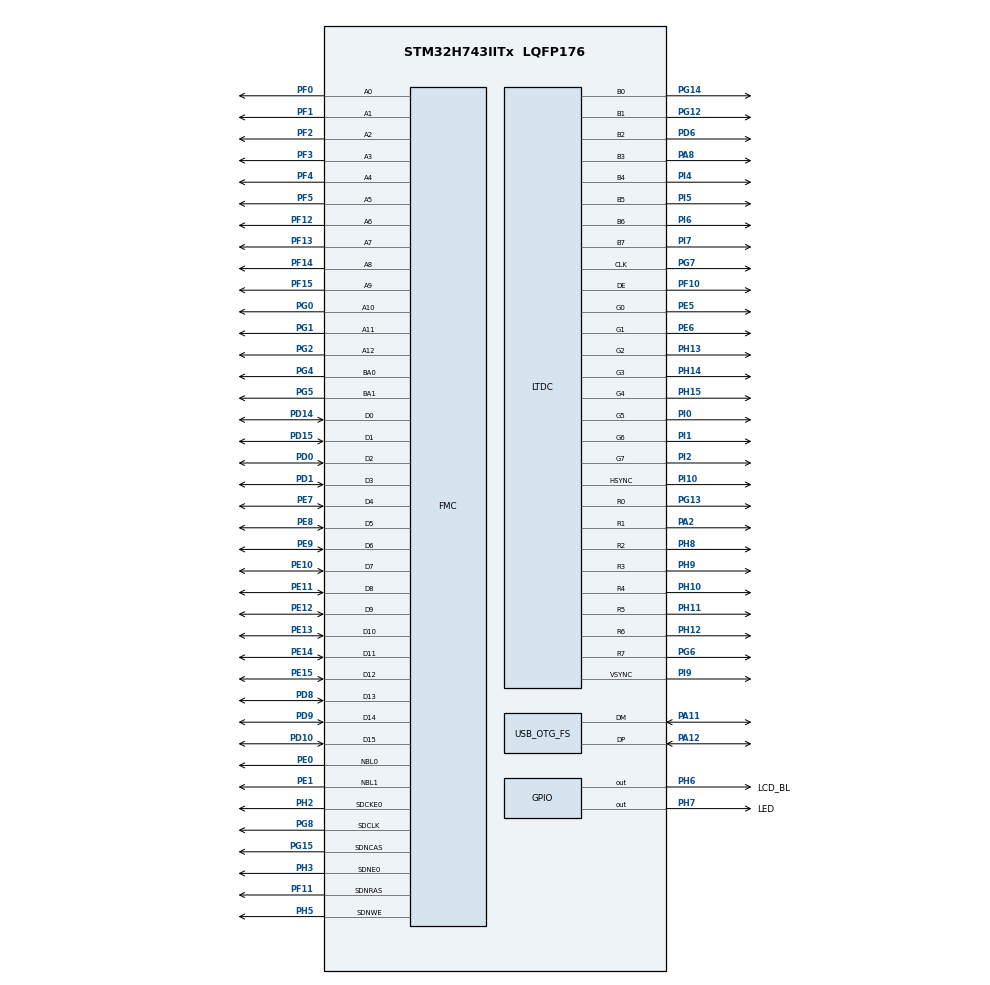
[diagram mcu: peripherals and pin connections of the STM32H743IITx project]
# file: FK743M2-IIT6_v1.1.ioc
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CORTEX_M7.default_mode_Activation=1
DMA2D.ColorMode=DMA2D_OUTPUT_RGB565
FMC.CASLatency1=FMC_SDRAM_CAS_LATENCY_3
FMC.ColumnBitsNumber1=FMC_SDRAM_COLUMN_BITS_NUM_9
FMC.ExitSelfRefreshDelay1=8
FMC.LoadToActiveDelay1=5
FMC.RCDDelay1=2
FMC.RPDelay1=2
FMC.RPDelay2=2
FMC.ReadPipeDelay1=FMC_SDRAM_RPIPE_DELAY_1
FMC.ReadPipeDelay2=FMC_SDRAM_RPIPE_DELAY_1
FMC.RowCycleDelay1=6
FMC.RowCycleDelay2=6
FMC.SDClockPeriod1=FMC_SDRAM_CLOCK_PERIOD_2
FMC.SDClockPeriod2=FMC_SDRAM_CLOCK_PERIOD_2
FMC.SelfRefreshTime1=4
FMC.WriteRecoveryTime1=2
LTDC.ActiveH=600
LTDC.ActiveW=1024
LTDC.Alpha_L0=0xFF
LTDC.BlendingFactor1_L0=LTDC_BLENDING_FACTOR1_PAxCA
LTDC.BlendingFactor1_L1=LTDC_BLENDING_FACTOR1_PAxCA
LTDC.BlendingFactor2_L0=LTDC_BLENDING_FACTOR2_PAxCA
LTDC.BlendingFactor2_L1=LTDC_BLENDING_FACTOR2_PAxCA
LTDC.FBStartAdress_L0=0xC0000000
LTDC.FBStartAdress_L1=0xC0200000
LTDC.HBP=140
LTDC.HFP=160
LTDC.HSync=20
LTDC.ImageHeight_L0=600
LTDC.ImageHeight_L1=600
LTDC.ImageWidth_L0=1024
LTDC.ImageWidth_L1=1024
LTDC.PixelFormat_L0=LTDC_PIXEL_FORMAT_RGB565
LTDC.PixelFormat_L1=LTDC_PIXEL_FORMAT_RGB565
LTDC.VBP=20
LTDC.VFP=12
LTDC.VSync=3
LTDC.WindowX1_L0=1024
LTDC.WindowX1_L1=1024
LTDC.WindowY1_L0=600
LTDC.WindowY1_L1=600
Mcu.Family=STM32H7
Mcu.Name=STM32H743IITx
Mcu.Package=LQFP176
NVIC.OTG_FS_IRQn=true\:0\:0\:false\:false\:true\:true\:true\:true
NVIC.PriorityGroup=NVIC_PRIORITYGROUP_4
PA11.Mode=Device_Only
PA11.Signal=USB_OTG_FS_DM
PA12.Mode=Device_Only
PA12.Signal=USB_OTG_FS_DP
PA2.Mode=RGB888
PA2.Signal=LTDC_R1
PA8.Mode=RGB888
PA8.Signal=LTDC_B3
PC14-OSC32_IN\ (OSC32_IN).Mode=LSE-External-Oscillator
PC14-OSC32_IN\ (OSC32_IN).Signal=RCC_OSC32_IN
PC15-OSC32_OUT\ (OSC32_OUT).Mode=LSE-External-Oscillator
PC15-OSC32_OUT\ (OSC32_OUT).Signal=RCC_OSC32_OUT
PD0.Signal=FMC_D2_DA2
PD1.Signal=FMC_D3_DA3
PD10.Signal=FMC_D15_DA15
PD14.Signal=FMC_D0_DA0
PD15.Signal=FMC_D1_DA1
PD6.Mode=RGB888
PD6.Signal=LTDC_B2
PD8.Signal=FMC_D13_DA13
PD9.Signal=FMC_D14_DA14
PE0.Signal=FMC_NBL0
PE1.Signal=FMC_NBL1
PE10.Signal=FMC_D7_DA7
PE11.Signal=FMC_D8_DA8
PE12.Signal=FMC_D9_DA9
PE13.Signal=FMC_D10_DA10
PE14.Signal=FMC_D11_DA11
PE15.Signal=FMC_D12_DA12
PE5.Mode=RGB888
PE5.Signal=LTDC_G0
PE6.Mode=RGB888
PE6.Signal=LTDC_G1
PE7.Signal=FMC_D4_DA4
PE8.Signal=FMC_D5_DA5
PE9.Signal=FMC_D6_DA6
PF0.Signal=FMC_A0
PF1.Signal=FMC_A1
PF10.Mode=RGB888
PF10.Signal=LTDC_DE
PF11.Signal=FMC_SDNRAS
PF12.Signal=FMC_A6
PF13.Signal=FMC_A7
PF14.Signal=FMC_A8
PF15.Signal=FMC_A9
PF2.Signal=FMC_A2
PF3.Signal=FMC_A3
PF4.Signal=FMC_A4
PF5.Signal=FMC_A5
PG0.Signal=FMC_A10
PG1.Signal=FMC_A11
PG12.Mode=RGB888
PG12.Signal=LTDC_B1
PG13.Mode=RGB888
PG13.Signal=LTDC_R0
PG14.Mode=RGB888
PG14.Signal=LTDC_B0
PG15.Signal=FMC_SDNCAS
PG2.Signal=FMC_A12
PG4.Signal=FMC_A14_BA0
PG5.Signal=FMC_A15_BA1
PG6.Mode=RGB888
PG6.Signal=LTDC_R7
PG7.Mode=RGB888
PG7.Signal=LTDC_CLK
PG8.Signal=FMC_SDCLK
PH0-OSC_IN\ (PH0).Mode=HSE-External-Oscillator
PH0-OSC_IN\ (PH0).Signal=RCC_OSC_IN
PH1-OSC_OUT\ (PH1).Mode=HSE-External-Oscillator
PH1-OSC_OUT\ (PH1).Signal=RCC_OSC_OUT
PH10.Mode=RGB888
PH10.Signal=LTDC_R4
PH11.Mode=RGB888
PH11.Signal=LTDC_R5
PH12.Mode=RGB888
PH12.Signal=LTDC_R6
PH13.Mode=RGB888
PH13.Signal=LTDC_G2
PH14.Mode=RGB888
PH14.Signal=LTDC_G3
PH15.Mode=RGB888
PH15.Signal=LTDC_G4
PH2.Mode=SdramChipSelect1_1
PH2.Signal=FMC_SDCKE0
PH3.Mode=SdramChipSelect1_1
PH3.Signal=FMC_SDNE0
PH5.Signal=FMC_SDNWE
PH6.GPIO_Label=LCD_BL
PH6.GPIO_PuPd=GPIO_PULLDOWN
PH6.PinState=GPIO_PIN_SET
PH6.Signal=GPIO_Output
PH7.GPIO_Label=LED
PH7.Signal=GPIO_Output
PH8.Mode=RGB888
PH8.Signal=LTDC_R2
PH9.Mode=RGB888
PH9.Signal=LTDC_R3
PI0.Mode=RGB888
PI0.Signal=LTDC_G5
PI1.Mode=RGB888
PI1.Signal=LTDC_G6
PI10.Mode=RGB888
PI10.Signal=LTDC_HSYNC
PI2.Mode=RGB888
PI2.Signal=LTDC_G7
PI4.Mode=RGB888
PI4.Signal=LTDC_B4
PI5.Mode=RGB888
PI5.Signal=LTDC_B5
PI6.Mode=RGB888
PI6.Signal=LTDC_B6
PI7.Mode=RGB888
PI7.Signal=LTDC_B7
PI9.Mode=RGB888
PI9.Signal=LTDC_VSYNC
ProjectManager.HeapSize=0x200
ProjectManager.StackSize=0x400
ProjectManager.TargetToolchain=STM32CubeIDE
RCC.ADCFreq_Value=50390625
RCC.APB1Freq_Value=100000000
RCC.APB2Freq_Value=100000000
RCC.APB3Freq_Value=100000000
RCC.APB4Freq_Value=100000000
RCC.CortexFreq_Value=400000000
RCC.D1PPRE=RCC_APB3_DIV2
RCC.D2PPRE1=RCC_APB1_DIV2
RCC.D2PPRE2=RCC_APB2_DIV2
RCC.D3PPRE=RCC_APB4_DIV2
RCC.DIVM1=2
RCC.DIVN1=64
RCC.DIVN3=192
RCC.DIVQ1=17
RCC.DIVR3=6
RCC.HCLKFreq_Value=200000000
RCC.HPRE=RCC_HCLK_DIV2
RCC.LockedElements=D1CPREOutput
RCC.PLLFRACN=0
RCC.PLLSourceVirtual=RCC_PLLSOURCE_HSE
RCC.SYSCLKFreq_VALUE=400000000
RCC.SYSCLKSource=RCC_SYSCLKSOURCE_PLLCLK
RCC.USBFreq_Value=47058823.52941176
SH.FMC_A0.0=FMC_A0,13b-sda1
SH.FMC_A1.0=FMC_A1,13b-sda1
SH.FMC_A10.0=FMC_A10,13b-sda1
SH.FMC_A11.0=FMC_A11,13b-sda1
SH.FMC_A12.0=FMC_A12,13b-sda1
SH.FMC_A14_BA0.0=FMC_BA0,FourSdramBanks1
SH.FMC_A15_BA1.0=FMC_BA1,FourSdramBanks1
SH.FMC_A2.0=FMC_A2,13b-sda1
SH.FMC_A3.0=FMC_A3,13b-sda1
SH.FMC_A4.0=FMC_A4,13b-sda1
SH.FMC_A5.0=FMC_A5,13b-sda1
SH.FMC_A6.0=FMC_A6,13b-sda1
SH.FMC_A7.0=FMC_A7,13b-sda1
SH.FMC_A8.0=FMC_A8,13b-sda1
SH.FMC_A9.0=FMC_A9,13b-sda1
SH.FMC_D0_DA0.0=FMC_D0,sd-16b-d1
SH.FMC_D10_DA10.0=FMC_D10,sd-16b-d1
SH.FMC_D11_DA11.0=FMC_D11,sd-16b-d1
SH.FMC_D12_DA12.0=FMC_D12,sd-16b-d1
SH.FMC_D13_DA13.0=FMC_D13,sd-16b-d1
SH.FMC_D14_DA14.0=FMC_D14,sd-16b-d1
SH.FMC_D15_DA15.0=FMC_D15,sd-16b-d1
SH.FMC_D1_DA1.0=FMC_D1,sd-16b-d1
SH.FMC_D2_DA2.0=FMC_D2,sd-16b-d1
SH.FMC_D3_DA3.0=FMC_D3,sd-16b-d1
SH.FMC_D4_DA4.0=FMC_D4,sd-16b-d1
SH.FMC_D5_DA5.0=FMC_D5,sd-16b-d1
SH.FMC_D6_DA6.0=FMC_D6,sd-16b-d1
SH.FMC_D7_DA7.0=FMC_D7,sd-16b-d1
SH.FMC_D8_DA8.0=FMC_D8,sd-16b-d1
SH.FMC_D9_DA9.0=FMC_D9,sd-16b-d1
SH.FMC_NBL0.0=FMC_NBL0,Sd2ByteEnable1
SH.FMC_NBL1.0=FMC_NBL1,Sd2ByteEnable1
SH.FMC_SDCLK.0=FMC_SDCLK,13b-sda1
SH.FMC_SDNCAS.0=FMC_SDNCAS,13b-sda1
SH.FMC_SDNRAS.0=FMC_SDNRAS,13b-sda1
SH.FMC_SDNWE.0=FMC_SDNWE,13b-sda1
USB_DEVICE.CLASS_NAME_FS=CDC
USB_DEVICE.VirtualMode-CDC_FS=Cdc
USB_DEVICE.VirtualModeFS=Cdc_FS
USB_OTG_FS.VirtualMode=Device_Only
VP_DMA2D_VS_DMA2D.Mode=DMA2D_Activate
VP_MEMORYMAP_VS_MEMORYMAP.Mode=CurAppReg
VP_USB_DEVICE_VS_USB_DEVICE_CDC_FS.Mode=CDC_FS
board=custom

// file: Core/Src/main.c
/* USER CODE BEGIN Header */
/**
 ******************************************************************************
 * @file           : main.c
 * @brief          : Main program body
 ******************************************************************************
 * @attention
 *
 * Copyright (c) 2026 STMicroelectronics.
 * All rights reserved.
 *
 * This software is licensed under terms that can be found in the LICENSE file
 * in the root directory of this software component.
 * If no LICENSE file comes with this software, it is provided AS-IS.
 *
 ******************************************************************************
 */
/* USER CODE END Header */
#include "main.h"
#include "dma2d.h"
#include "ltdc.h"
#include "usb_device.h"
#include "gpio.h"
#include "fmc.h"

/* USER CODE BEGIN Includes */
#include <stdio.h>
#include "usbd_cdc_if.h"
#include "w9825g6kh.h"

/* USER CODE END Includes */

/* USER CODE BEGIN PD */
#define SDRAM_BANK_ADDR                 ((uint32_t)0xC0000000)
/* USER CODE END PD */

/* USER CODE BEGIN PM */
W9825G6KH_InitTypeDef sdram_conf;
/* USER CODE END PM */

/* USER CODE BEGIN PV */
extern USBD_HandleTypeDef hUsbDeviceFS;
extern uint8_t CDC_Tx_Ready;

/* USER CODE END PV */

void SystemClock_Config(void);
static void MPU_Config(void);
/* USER CODE BEGIN PFP */
int _write(int file, char *ptr, int len);
void BoardMPU_Config(void);
/* USER CODE END PFP */

int main(void)
{

  /* MPU Configuration--------------------------------------------------------*/
  MPU_Config();

  /* MCU Configuration--------------------------------------------------------*/

  /* Reset of all peripherals, Initializes the Flash interface and the Systick. */
  HAL_Init();

  /* USER CODE BEGIN Init */
  BoardMPU_Config();
  /* USER CODE END Init */

  /* Configure the system clock */
  SystemClock_Config();

  /* Initialize all configured peripherals */
  MX_GPIO_Init();
  MX_USB_DEVICE_Init();
  MX_FMC_Init();
  MX_LTDC_Init();
  MX_DMA2D_Init();
  /* USER CODE BEGIN 2 */
	HAL_Delay(3000);
	printf("FK743M2-IIT6 USB CDC ready!\r\n");
	W9825G6KH_MemoryTest(0, 32*1024); /* Test first 1KB */

  /* USER CODE END 2 */

  /* Infinite loop */
  /* USER CODE BEGIN WHILE */
	while (1)
	{
		printf("Hello!\n");
		HAL_GPIO_TogglePin(LED_GPIO_Port, LED_Pin);
		HAL_Delay(100);
    /* USER CODE END WHILE */

	}
}

void SystemClock_Config(void)
{
  RCC_OscInitTypeDef RCC_OscInitStruct = {0};
  RCC_ClkInitTypeDef RCC_ClkInitStruct = {0};

  /** Supply configuration update enable
  */
  HAL_PWREx_ConfigSupply(PWR_LDO_SUPPLY);

  /** Configure the main internal regulator output voltage
  */
  __HAL_PWR_VOLTAGESCALING_CONFIG(PWR_REGULATOR_VOLTAGE_SCALE1);

  while(!__HAL_PWR_GET_FLAG(PWR_FLAG_VOSRDY)) {}

  /** Initializes the RCC Oscillators according to the specified parameters
  * in the RCC_OscInitTypeDef structure.
  */
  RCC_OscInitStruct.OscillatorType = RCC_OSCILLATORTYPE_HSE;
  RCC_OscInitStruct.HSEState = RCC_HSE_ON;
  RCC_OscInitStruct.PLL.PLLState = RCC_PLL_ON;
  RCC_OscInitStruct.PLL.PLLSource = RCC_PLLSOURCE_HSE;
  RCC_OscInitStruct.PLL.PLLM = 2;
  RCC_OscInitStruct.PLL.PLLN = 64;
  RCC_OscInitStruct.PLL.PLLP = 2;
  RCC_OscInitStruct.PLL.PLLQ = 17;
  RCC_OscInitStruct.PLL.PLLR = 2;
  RCC_OscInitStruct.PLL.PLLRGE = RCC_PLL1VCIRANGE_3;
  RCC_OscInitStruct.PLL.PLLVCOSEL = RCC_PLL1VCOWIDE;
  RCC_OscInitStruct.PLL.PLLFRACN = 0;
  if (HAL_RCC_OscConfig(&RCC_OscInitStruct) != HAL_OK)
  {
    Error_Handler();
  }

  /** Initializes the CPU, AHB and APB buses clocks
  */
  RCC_ClkInitStruct.ClockType = RCC_CLOCKTYPE_HCLK|RCC_CLOCKTYPE_SYSCLK
                              |RCC_CLOCKTYPE_PCLK1|RCC_CLOCKTYPE_PCLK2
                              |RCC_CLOCKTYPE_D3PCLK1|RCC_CLOCKTYPE_D1PCLK1;
  RCC_ClkInitStruct.SYSCLKSource = RCC_SYSCLKSOURCE_PLLCLK;
  RCC_ClkInitStruct.SYSCLKDivider = RCC_SYSCLK_DIV1;
  RCC_ClkInitStruct.AHBCLKDivider = RCC_HCLK_DIV2;
  RCC_ClkInitStruct.APB3CLKDivider = RCC_APB3_DIV2;
  RCC_ClkInitStruct.APB1CLKDivider = RCC_APB1_DIV2;
  RCC_ClkInitStruct.APB2CLKDivider = RCC_APB2_DIV2;
  RCC_ClkInitStruct.APB4CLKDivider = RCC_APB4_DIV2;

  if (HAL_RCC_ClockConfig(&RCC_ClkInitStruct, FLASH_LATENCY_2) != HAL_OK)
  {
    Error_Handler();
  }
}

/* USER CODE BEGIN 4 */
int _write(int file, char *ptr, int len)
{
	if (file != 1 || len <= 0)
		return len;

	/* Если USB не подключён/не сконфигурирован — пропускаем */
	if (hUsbDeviceFS.dev_state != USBD_STATE_CONFIGURED)
		return len;

	/* Ждём готовности предыдущей передачи */
	uint32_t timeout = 150000;   // ~3-5 мс
	while (CDC_Tx_Ready == 0 && timeout--)
	{
		__NOP();
	}

	if (CDC_Tx_Ready)
	{
		CDC_Transmit_FS((uint8_t*) ptr, (uint16_t) len);
		CDC_Tx_Ready = 0;
	}

	return len;
}

void BoardMPU_Config(void)
{
    MPU_Region_InitTypeDef MPU_InitStruct = {0};
    HAL_MPU_Disable();

    // Регион 0: вся память запрещена, кроме подобластей 0,1,2 (для FLASH/SRAM)
    MPU_InitStruct.Enable = MPU_REGION_ENABLE;
    MPU_InitStruct.Number = MPU_REGION_NUMBER0;
    MPU_InitStruct.BaseAddress = 0x0;
    MPU_InitStruct.Size = MPU_REGION_SIZE_4GB;
    MPU_InitStruct.SubRegionDisable = 0x87;   // разрешаем подобласти 0,1,2
    MPU_InitStruct.TypeExtField = MPU_TEX_LEVEL0;
    MPU_InitStruct.AccessPermission = MPU_REGION_NO_ACCESS;
    MPU_InitStruct.DisableExec = MPU_INSTRUCTION_ACCESS_DISABLE;
    MPU_InitStruct.IsShareable = MPU_ACCESS_SHAREABLE;
    MPU_InitStruct.IsCacheable = MPU_ACCESS_NOT_CACHEABLE;
    MPU_InitStruct.IsBufferable = MPU_ACCESS_NOT_BUFFERABLE;
    HAL_MPU_ConfigRegion(&MPU_InitStruct);

    // Регион 1: SDRAM (0xC0000000, 32 МБ) – полный доступ, без кэша
    MPU_InitStruct.Enable = MPU_REGION_ENABLE;
    MPU_InitStruct.Number = MPU_REGION_NUMBER1;
    MPU_InitStruct.BaseAddress = 0xC0000000;
    MPU_InitStruct.Size = MPU_REGION_SIZE_32MB;
    MPU_InitStruct.SubRegionDisable = 0x0;
    MPU_InitStruct.TypeExtField = MPU_TEX_LEVEL0;
    MPU_InitStruct.AccessPermission = MPU_REGION_FULL_ACCESS;
    MPU_InitStruct.DisableExec = MPU_INSTRUCTION_ACCESS_ENABLE;
    MPU_InitStruct.IsShareable = MPU_ACCESS_NOT_SHAREABLE;
    MPU_InitStruct.IsCacheable = MPU_ACCESS_NOT_CACHEABLE;
    MPU_InitStruct.IsBufferable = MPU_ACCESS_NOT_BUFFERABLE;
    HAL_MPU_ConfigRegion(&MPU_InitStruct);

    HAL_MPU_Enable(MPU_PRIVILEGED_DEFAULT);
}
/* USER CODE END 4 */

 /* MPU Configuration */

void MPU_Config(void)
{
  MPU_Region_InitTypeDef MPU_InitStruct = {0};

  /* Disables the MPU */
  HAL_MPU_Disable();

  /** Initializes and configures the Region and the memory to be protected
  */
  MPU_InitStruct.Enable = MPU_REGION_ENABLE;
  MPU_InitStruct.Number = MPU_REGION_NUMBER0;
  MPU_InitStruct.BaseAddress = 0x0;
  MPU_InitStruct.Size = MPU_REGION_SIZE_4GB;
  MPU_InitStruct.SubRegionDisable = 0x87;
  MPU_InitStruct.TypeExtField = MPU_TEX_LEVEL0;
  MPU_InitStruct.AccessPermission = MPU_REGION_NO_ACCESS;
  MPU_InitStruct.DisableExec = MPU_INSTRUCTION_ACCESS_DISABLE;
  MPU_InitStruct.IsShareable = MPU_ACCESS_SHAREABLE;
  MPU_InitStruct.IsCacheable = MPU_ACCESS_NOT_CACHEABLE;
  MPU_InitStruct.IsBufferable = MPU_ACCESS_NOT_BUFFERABLE;

  HAL_MPU_ConfigRegion(&MPU_InitStruct);
  /* Enables the MPU */
  HAL_MPU_Enable(MPU_PRIVILEGED_DEFAULT);

}

void Error_Handler(void)
{
	__disable_irq();
	while (1)
	{
	}
}
